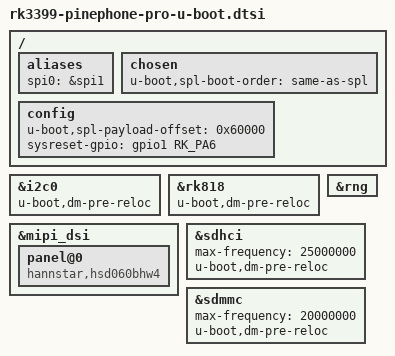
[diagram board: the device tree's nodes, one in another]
// SPDX-License-Identifier: GPL-2.0+
/*
 * Copyright (C) 2019 Peter Robinson <pbrobinson at gmail.com>
 */

#include "rk3399-u-boot.dtsi"
#include "rk3399-sdram-lpddr4-100.dtsi"

/ {
	aliases {
		spi0 = &spi1;
	};

	chosen {
		u-boot,spl-boot-order = "same-as-spl", &sdhci, &sdmmc;
	};

	config {
		u-boot,spl-payload-offset = <0x60000>; /* @ 384KB */
		sysreset-gpio = <&gpio1 RK_PA6 GPIO_ACTIVE_HIGH>;
	};
};

&i2c0 {
	u-boot,dm-pre-reloc;
};

&rk818 {
	u-boot,dm-pre-reloc;
};

&mipi_dsi {
	panel@0 {
		compatible = "hannstar,hsd060bhw4", "simple-panel";
	};
};

&rng {
	status = "okay";
};

&sdhci {
	max-frequency = <25000000>;
	u-boot,dm-pre-reloc;
};

&sdmmc {
	max-frequency = <20000000>;
	u-boot,dm-pre-reloc;
};
